VERSION ""

NS_ :

BS_:

BU_: K2L_Tool MCP2517FD

BO_ 3221225472 VECTOR__INDEPENDENT_SIG_MSG: 0 Vector__XXX
 SG_ BitTime : 0|8@1+ (1,0) [0|0] "" Vector__XXX

BO_ 769 TX_RESPONSE: 64 MCP2517FD

BO_ 768 TX_REQUEST: 64 K2L_Tool

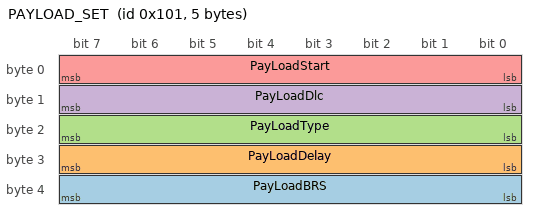
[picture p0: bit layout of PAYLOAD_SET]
BO_ 257 PAYLOAD_SET: 5 K2L_Tool
 SG_ PayLoadBRS : 32|8@1+ (1,0) [0|0] "" Vector__XXX
 SG_ PayLoadDelay : 24|8@1+ (1,0) [0|0] "" Vector__XXX
 SG_ PayLoadType : 16|8@1+ (1,0) [0|0] "" Vector__XXX
 SG_ PayLoadDlc : 8|8@1+ (1,0) [0|0] "" Vector__XXX
 SG_ PayLoadStart : 0|8@1+ (1,0) [0|0] "" Vector__XXX

BO_ 513 BUTTON_STATUS: 1 MCP2517FD
 SG_ ButtonStatus : 0|8@1+ (1,0) [0|0] ""  K2L_Tool

BO_ 512 LED_SET: 1 K2L_Tool
 SG_ LEDValue : 0|8@1+ (1,0) [0|0] ""  MCP2517FD

CM_ BO_ 3221225472 "This is a message for not used signals, created by Vector CANdb++ DBC OLE DB Provider.";
BA_DEF_ BO_  "CANFD_BRS" ENUM  "0","1";
BA_DEF_  "DBName" STRING ;
BA_DEF_  "BusType" STRING ;
BA_DEF_ BO_  "VFrameFormat" ENUM  "StandardCAN","ExtendedCAN","reserved","reserved","reserved","reserved","reserved","reserved","reserved","reserved","reserved","reserved","reserved","reserved","StandardCAN_FD","ExtendedCAN_FD";
BA_DEF_DEF_  "CANFD_BRS" "1";
BA_DEF_DEF_  "DBName" "";
BA_DEF_DEF_  "BusType" "";
BA_DEF_DEF_  "VFrameFormat" "StandardCAN";
BA_ "BusType" "CAN FD";
BA_ "DBName" "MCP2517FDDemo";
BA_ "VFrameFormat" BO_ 769 14;
BA_ "VFrameFormat" BO_ 768 14;
BA_ "VFrameFormat" BO_ 257 14;
BA_ "VFrameFormat" BO_ 513 14;
BA_ "VFrameFormat" BO_ 512 14;
